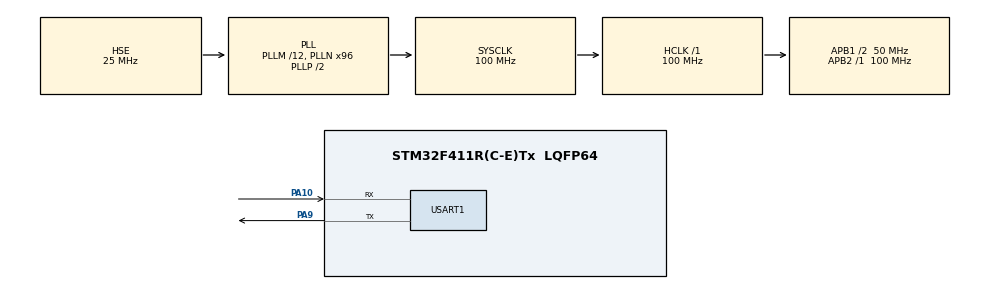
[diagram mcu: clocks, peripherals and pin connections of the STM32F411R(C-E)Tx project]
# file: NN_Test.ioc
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Mcu.Family=STM32F4
Mcu.Name=STM32F411R(C-E)Tx
Mcu.Package=LQFP64
NVIC.PriorityGroup=NVIC_PRIORITYGROUP_4
PA10.Mode=Asynchronous
PA10.Signal=USART1_RX
PA13.Mode=Serial_Wire
PA13.Signal=SYS_JTMS-SWDIO
PA14.Mode=Serial_Wire
PA14.Signal=SYS_JTCK-SWCLK
PA9.Mode=Asynchronous
PA9.Signal=USART1_TX
PC14-OSC32_IN.Mode=LSE-External-Oscillator
PC14-OSC32_IN.Signal=RCC_OSC32_IN
PC15-OSC32_OUT.Mode=LSE-External-Oscillator
PC15-OSC32_OUT.Signal=RCC_OSC32_OUT
PH0\ -\ OSC_IN.Mode=HSE-External-Oscillator
PH0\ -\ OSC_IN.Signal=RCC_OSC_IN
PH1\ -\ OSC_OUT.Mode=HSE-External-Oscillator
PH1\ -\ OSC_OUT.Signal=RCC_OSC_OUT
ProjectManager.HeapSize=0x800
ProjectManager.StackSize=0x800
ProjectManager.TargetToolchain=MDK-ARM V5.32
RCC.48MHZClocksFreq_Value=50000000
RCC.AHBFreq_Value=100000000
RCC.APB1CLKDivider=RCC_HCLK_DIV2
RCC.APB1Freq_Value=50000000
RCC.APB1TimFreq_Value=100000000
RCC.APB2Freq_Value=100000000
RCC.APB2TimFreq_Value=100000000
RCC.CortexFreq_Value=100000000
RCC.HCLKFreq_Value=100000000
RCC.HSE_VALUE=25000000
RCC.HSI_VALUE=16000000
RCC.PLLM=12
RCC.PLLN=96
RCC.PLLSourceVirtual=RCC_PLLSOURCE_HSE
RCC.SYSCLKFreq_VALUE=100000000
RCC.SYSCLKSource=RCC_SYSCLKSOURCE_PLLCLK
RCC.VCOOutputFreq_Value=200000000
STMicroelectronics.X-CUBE-AI.10.1.0.ActivationBufferSizeList=1872
STMicroelectronics.X-CUBE-AI.10.1.0.ActivationBuffers=pool0
STMicroelectronics.X-CUBE-AI.10.1.0.ActivationNames=pool0
STMicroelectronics.X-CUBE-AI.10.1.0.ActivationSizes=AI_SINE_CALCU_DATA_ACTIVATION_1_SIZE
STMicroelectronics.X-CUBE-AI.10.1.0.ApplicationCcDeviceJjApplication=SystemPerformance
STMicroelectronics.X-CUBE-AI.10.1.0.BSP.number=1
STMicroelectronics.X-CUBE-AI.10.1.0.HeapSize=0x800
STMicroelectronics.X-CUBE-AI.10.1.0.InternalRamActivationBufferMaxSize=AI_SINE_CALCU_DATA_ACTIVATIONS_SIZE
STMicroelectronics.X-CUBE-AI.10.1.0.LatestDirectoryUsed-b0ba31c8a8d679d93ad9060e7858808c115b051c8f76b7aa14d38eb7098f748e=C\:\\Users\\kingham\\Desktop
STMicroelectronics.X-CUBE-AI.10.1.0.MaximumNumberOfInputLayer=1
STMicroelectronics.X-CUBE-AI.10.1.0.MaximumNumberOfOutputLayer=1
STMicroelectronics.X-CUBE-AI.10.1.0.MaximumSizeOfInputLayer=1
STMicroelectronics.X-CUBE-AI.10.1.0.MaximumSizeOfOutputLayer=1
STMicroelectronics.X-CUBE-AI.10.1.0.ModelActualCompression-b0ba31c8a8d679d93ad9060e7858808c115b051c8f76b7aa14d38eb7098f748e=0.0
STMicroelectronics.X-CUBE-AI.10.1.0.ModelCompression-b0ba31c8a8d679d93ad9060e7858808c115b051c8f76b7aa14d38eb7098f748e=None
STMicroelectronics.X-CUBE-AI.10.1.0.ModelFlashOccupation-b0ba31c8a8d679d93ad9060e7858808c115b051c8f76b7aa14d38eb7098f748e=10596
STMicroelectronics.X-CUBE-AI.10.1.0.ModelHashList=b0ba31c8a8d679d93ad9060e7858808c115b051c8f76b7aa14d38eb7098f748e
STMicroelectronics.X-CUBE-AI.10.1.0.ModelKind-b0ba31c8a8d679d93ad9060e7858808c115b051c8f76b7aa14d38eb7098f748e=TFLITE
STMicroelectronics.X-CUBE-AI.10.1.0.ModelMacc-b0ba31c8a8d679d93ad9060e7858808c115b051c8f76b7aa14d38eb7098f748e=231
STMicroelectronics.X-CUBE-AI.10.1.0.ModelName-b0ba31c8a8d679d93ad9060e7858808c115b051c8f76b7aa14d38eb7098f748e=sine_calcu
STMicroelectronics.X-CUBE-AI.10.1.0.ModelNameList=sine_calcu
STMicroelectronics.X-CUBE-AI.10.1.0.ModelRamOccupation-b0ba31c8a8d679d93ad9060e7858808c115b051c8f76b7aa14d38eb7098f748e=1872
STMicroelectronics.X-CUBE-AI.10.1.0.ModelStructureFile-b0ba31c8a8d679d93ad9060e7858808c115b051c8f76b7aa14d38eb7098f748e=C\:\\Users\\kingham\\Desktop\\sine_calcu.tflite
STMicroelectronics.X-CUBE-AI.10.1.0.ModelType-b0ba31c8a8d679d93ad9060e7858808c115b051c8f76b7aa14d38eb7098f748e=STM32Cube.AI MCU runtime
STMicroelectronics.X-CUBE-AI.10.1.0.ReadyForCodeGeneration=true
STMicroelectronics.X-CUBE-AI.10.1.0.StackSize=0x800
STMicroelectronics.X-CUBE-AI.10.1.0.WorkingBufferStartAddrList=0xFFFFFFFF
STMicroelectronics.X-CUBE-AI.10.1.0.XAaCUBEAaAICcArtificialOoIntelligenceJjCore=true
STMicroelectronics.X-CUBE-AI.10.1.0.copyWeightToRam=false
STMicroelectronics.X-CUBE-AI.10.1.0.copyWeightToRam-b0ba31c8a8d679d93ad9060e7858808c115b051c8f76b7aa14d38eb7098f748e=false
STMicroelectronics.X-CUBE-AI.10.1.0.customLayerConfigEnabled=false
STMicroelectronics.X-CUBE-AI.10.1.0.customLayerConfigEnabled-b0ba31c8a8d679d93ad9060e7858808c115b051c8f76b7aa14d38eb7098f748e=false
STMicroelectronics.X-CUBE-AI.10.1.0.noOnnxIoTranspose=false
STMicroelectronics.X-CUBE-AI.10.1.0.noOnnxIoTranspose-b0ba31c8a8d679d93ad9060e7858808c115b051c8f76b7aa14d38eb7098f748e=false
STMicroelectronics.X-CUBE-AI.10.1.0.useInputAllocation=true
STMicroelectronics.X-CUBE-AI.10.1.0.useInputAllocation-b0ba31c8a8d679d93ad9060e7858808c115b051c8f76b7aa14d38eb7098f748e=true
STMicroelectronics.X-CUBE-AI.10.1.0.useOutputAllocation=true
STMicroelectronics.X-CUBE-AI.10.1.0.useOutputAllocation-b0ba31c8a8d679d93ad9060e7858808c115b051c8f76b7aa14d38eb7098f748e=true
STMicroelectronics.X-CUBE-AI.10.1.00.BSP.STBoard=false
STMicroelectronics.X-CUBE-AI.10.1.00.BSP.api=Unknown
STMicroelectronics.X-CUBE-AI.10.1.00.BSP.condition=\!SEMDeviceJjApplicationJjApplicationTemplate
STMicroelectronics.X-CUBE-AI.10.1.00.BSP.instance=USART1
STMicroelectronics.X-CUBE-AI.10.1.00.BSP.ip=USART
STMicroelectronics.X-CUBE-AI.10.1.00.BSP.mode=Asynchronous
STMicroelectronics.X-CUBE-AI.10.1.00.BSP.name=COM Port
STMicroelectronics.X-CUBE-AI.10.1.00.BSP.solution=USART1
USART1.VirtualMode=VM_ASYNC
VP_STMicroelectronics.X-CUBE-AI_VS_ArtificialOoIntelligenceJjXAaCUBEAaAI_10.1.0.Mode=ArtificialOoIntelligenceJjXAaCUBEAaAI
VP_STMicroelectronics.X-CUBE-AI_VS_DeviceJjApplication_10.1.0.Mode=DeviceJjApplication
board=custom

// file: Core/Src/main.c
/* USER CODE BEGIN Header */
/**
  ******************************************************************************
  * @file           : main.c
  * @brief          : Main program body
  ******************************************************************************
  * @attention
  *
  * Copyright (c) 2026 STMicroelectronics.
  * All rights reserved.
  *
  * This software is licensed under terms that can be found in the LICENSE file
  * in the root directory of this software component.
  * If no LICENSE file comes with this software, it is provided AS-IS.
  *
  ******************************************************************************
  */
/* USER CODE END Header */
#include "main.h"
#include "usart.h"
#include "gpio.h"
#include "app_x-cube-ai.h"

void SystemClock_Config(void);

int main(void)
{

  /* MCU Configuration--------------------------------------------------------*/

  /* Reset of all peripherals, Initializes the Flash interface and the Systick. */
  HAL_Init();

  /* Configure the system clock */
  SystemClock_Config();

  /* Initialize all configured peripherals */
  MX_GPIO_Init();
  MX_USART1_UART_Init();
  MX_X_CUBE_AI_Init();

  /* Infinite loop */
  while (1)
  {

		MX_X_CUBE_AI_Process();
    /* USER CODE BEGIN 3 */
		HAL_Delay(100);
  }
  /* USER CODE END 3 */
}

void SystemClock_Config(void)
{
  RCC_OscInitTypeDef RCC_OscInitStruct = {0};
  RCC_ClkInitTypeDef RCC_ClkInitStruct = {0};

  /** Configure the main internal regulator output voltage
  */
  __HAL_RCC_PWR_CLK_ENABLE();
  __HAL_PWR_VOLTAGESCALING_CONFIG(PWR_REGULATOR_VOLTAGE_SCALE1);

  /** Initializes the RCC Oscillators according to the specified parameters
  * in the RCC_OscInitTypeDef structure.
  */
  RCC_OscInitStruct.OscillatorType = RCC_OSCILLATORTYPE_HSE;
  RCC_OscInitStruct.HSEState = RCC_HSE_ON;
  RCC_OscInitStruct.PLL.PLLState = RCC_PLL_ON;
  RCC_OscInitStruct.PLL.PLLSource = RCC_PLLSOURCE_HSE;
  RCC_OscInitStruct.PLL.PLLM = 12;
  RCC_OscInitStruct.PLL.PLLN = 96;
  RCC_OscInitStruct.PLL.PLLP = RCC_PLLP_DIV2;
  RCC_OscInitStruct.PLL.PLLQ = 4;
  if (HAL_RCC_OscConfig(&RCC_OscInitStruct) != HAL_OK)
  {
    Error_Handler();
  }

  /** Initializes the CPU, AHB and APB buses clocks
  */
  RCC_ClkInitStruct.ClockType = RCC_CLOCKTYPE_HCLK|RCC_CLOCKTYPE_SYSCLK
                              |RCC_CLOCKTYPE_PCLK1|RCC_CLOCKTYPE_PCLK2;
  RCC_ClkInitStruct.SYSCLKSource = RCC_SYSCLKSOURCE_PLLCLK;
  RCC_ClkInitStruct.AHBCLKDivider = RCC_SYSCLK_DIV1;
  RCC_ClkInitStruct.APB1CLKDivider = RCC_HCLK_DIV2;
  RCC_ClkInitStruct.APB2CLKDivider = RCC_HCLK_DIV1;

  if (HAL_RCC_ClockConfig(&RCC_ClkInitStruct, FLASH_LATENCY_3) != HAL_OK)
  {
    Error_Handler();
  }
}

void Error_Handler(void)
{
  __disable_irq();
  while (1)
  {
  }
}
